# CBASS_RC0_QOS register map
Vendor: Texas Instruments
Peripheral module from a debugger description file (folder J7_AHP).
Registers are 32-bit, read-write, reset 0x0 unless marked. A register's access mark holds for its fields unless they carry their own. Offsets are as the file gives them; lines under a group give offsets from that group; [hi:lo] are bit positions; {n}, {i} and the like mark numbered series; 'fields as' and 'values as' point back to an identical list; <NAME> marks a mode.

## CBASS_RC0_QOS
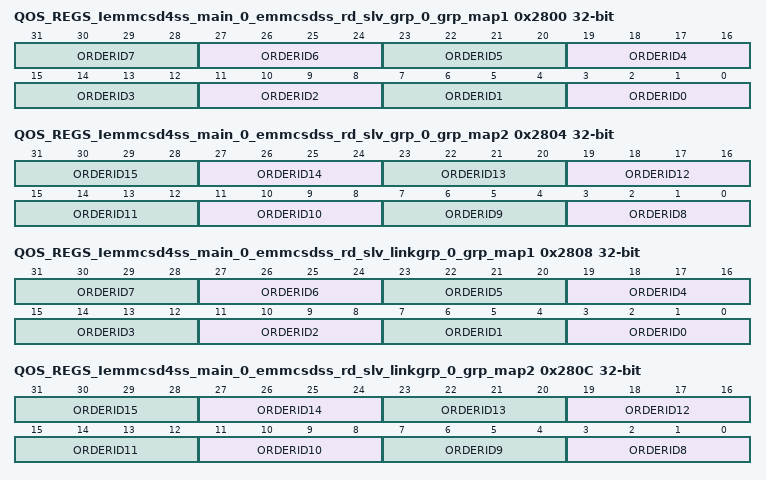
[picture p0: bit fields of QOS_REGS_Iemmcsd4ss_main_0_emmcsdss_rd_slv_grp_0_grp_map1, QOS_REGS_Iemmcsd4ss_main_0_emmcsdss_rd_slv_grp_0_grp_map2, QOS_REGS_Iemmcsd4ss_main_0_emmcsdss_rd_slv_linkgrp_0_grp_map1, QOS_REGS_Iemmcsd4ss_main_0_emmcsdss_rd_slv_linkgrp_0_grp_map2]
0x2800 QOS_REGS_Iemmcsd4ss_main_0_emmcsdss_rd_slv_grp_0_grp_map1
  [4n+3:4n] ORDERID{n} (n=0..7) — orderid signal for {n}.
0x2804 QOS_REGS_Iemmcsd4ss_main_0_emmcsdss_rd_slv_grp_0_grp_map2
  [4n-29:4n-32] ORDERID{n} (n=8..15) — orderid signal for {n-8}.
0x2808 QOS_REGS_Iemmcsd4ss_main_0_emmcsdss_rd_slv_linkgrp_0_grp_map1
  [4n+3:4n] ORDERID{n} (n=0..7) — orderid signal for {n}.
0x280C QOS_REGS_Iemmcsd4ss_main_0_emmcsdss_rd_slv_linkgrp_0_grp_map2
  [4n-29:4n-32] ORDERID{n} (n=8..15) — orderid signal for {n-8}.
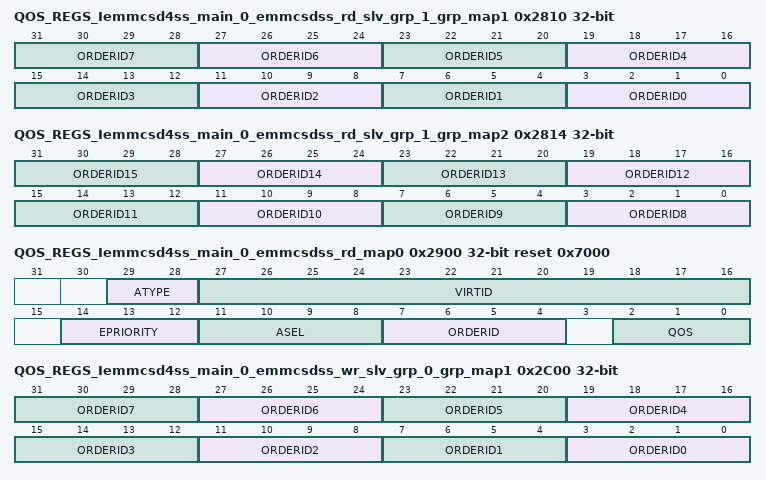
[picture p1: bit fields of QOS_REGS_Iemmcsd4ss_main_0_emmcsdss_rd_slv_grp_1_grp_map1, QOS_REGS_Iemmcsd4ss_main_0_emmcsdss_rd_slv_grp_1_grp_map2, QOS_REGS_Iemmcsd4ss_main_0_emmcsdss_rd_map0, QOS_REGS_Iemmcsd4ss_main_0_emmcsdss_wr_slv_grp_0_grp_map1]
0x2810 QOS_REGS_Iemmcsd4ss_main_0_emmcsdss_rd_slv_grp_1_grp_map1
  [4n+3:4n] ORDERID{n} (n=0..7) — orderid signal for {n}.
0x2814 QOS_REGS_Iemmcsd4ss_main_0_emmcsdss_rd_slv_grp_1_grp_map2
  [4n-29:4n-32] ORDERID{n} (n=8..15) — orderid signal for {n-8}.
0x2900 QOS_REGS_Iemmcsd4ss_main_0_emmcsdss_rd_map0 reset 0x7000
  [29:28] ATYPE — epriority signal for channel N. 0 = physical. 1 = intermediate. 2 = virtual. 3 = physical with coherence.
  [27:16] VIRTID — virtid signal for channel N.
  [14:12] EPRIORITY — epriority signal for channel N.
  [11:8] ASEL — asel signal for channel N. 0 = SOC address. 1-15 = peripheral address.
  [7:4] ORDERID — orderid signal for channel N.
  [2:0] QOS — qos signal for channel N.
0x2C00 QOS_REGS_Iemmcsd4ss_main_0_emmcsdss_wr_slv_grp_0_grp_map1
  [4n+3:4n] ORDERID{n} (n=0..7) — orderid signal for {n}.
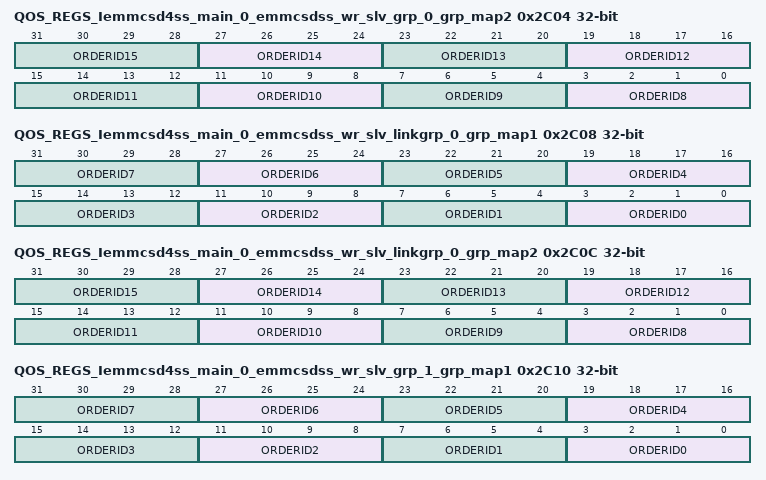
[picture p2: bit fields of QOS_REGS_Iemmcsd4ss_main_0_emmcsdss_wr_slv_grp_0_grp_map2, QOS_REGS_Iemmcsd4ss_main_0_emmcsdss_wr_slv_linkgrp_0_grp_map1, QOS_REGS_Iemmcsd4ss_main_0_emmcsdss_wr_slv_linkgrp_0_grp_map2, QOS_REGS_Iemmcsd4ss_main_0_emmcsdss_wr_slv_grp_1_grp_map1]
0x2C04 QOS_REGS_Iemmcsd4ss_main_0_emmcsdss_wr_slv_grp_0_grp_map2
  [4n-29:4n-32] ORDERID{n} (n=8..15) — orderid signal for {n-8}.
0x2C08 QOS_REGS_Iemmcsd4ss_main_0_emmcsdss_wr_slv_linkgrp_0_grp_map1
  [4n+3:4n] ORDERID{n} (n=0..7) — orderid signal for {n}.
0x2C0C QOS_REGS_Iemmcsd4ss_main_0_emmcsdss_wr_slv_linkgrp_0_grp_map2
  [4n-29:4n-32] ORDERID{n} (n=8..15) — orderid signal for {n-8}.
0x2C10 QOS_REGS_Iemmcsd4ss_main_0_emmcsdss_wr_slv_grp_1_grp_map1
  [4n+3:4n] ORDERID{n} (n=0..7) — orderid signal for {n}.
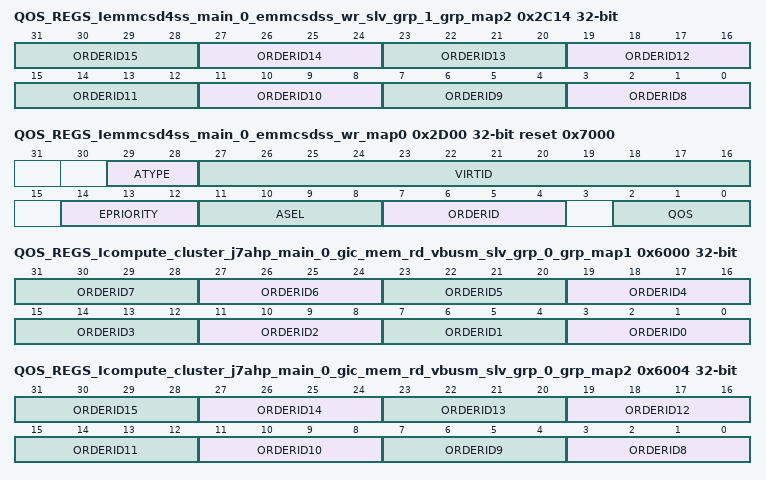
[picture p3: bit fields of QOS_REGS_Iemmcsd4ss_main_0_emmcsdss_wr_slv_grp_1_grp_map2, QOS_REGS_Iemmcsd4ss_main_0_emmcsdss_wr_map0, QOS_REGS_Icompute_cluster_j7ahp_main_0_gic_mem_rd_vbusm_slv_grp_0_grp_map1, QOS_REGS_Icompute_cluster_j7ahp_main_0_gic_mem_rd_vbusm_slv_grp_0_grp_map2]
0x2C14 QOS_REGS_Iemmcsd4ss_main_0_emmcsdss_wr_slv_grp_1_grp_map2
  [4n-29:4n-32] ORDERID{n} (n=8..15) — orderid signal for {n-8}.
0x2D00 QOS_REGS_Iemmcsd4ss_main_0_emmcsdss_wr_map0 reset 0x7000
  fields as QOS_REGS_Iemmcsd4ss_main_0_emmcsdss_rd_map0
0x6000 QOS_REGS_Icompute_cluster_j7ahp_main_0_gic_mem_rd_vbusm_slv_grp_0_grp_map1
  [4n+3:4n] ORDERID{n} (n=0..7) — orderid signal for {n}.
0x6004 QOS_REGS_Icompute_cluster_j7ahp_main_0_gic_mem_rd_vbusm_slv_grp_0_grp_map2
  [4n-29:4n-32] ORDERID{n} (n=8..15) — orderid signal for {n-8}.
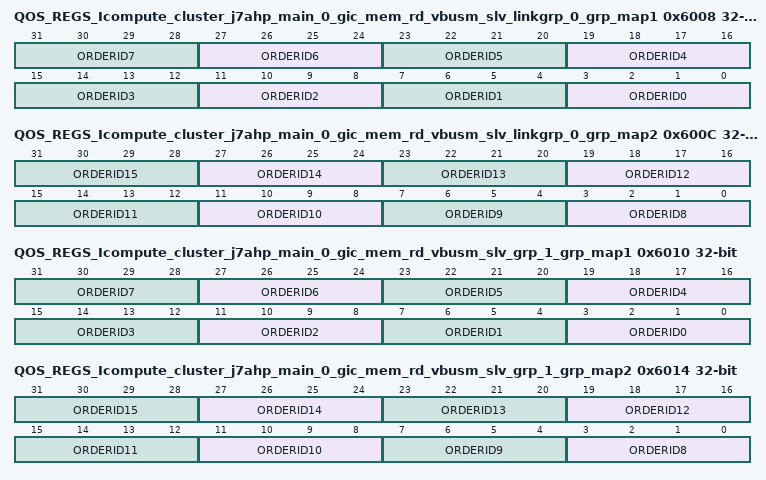
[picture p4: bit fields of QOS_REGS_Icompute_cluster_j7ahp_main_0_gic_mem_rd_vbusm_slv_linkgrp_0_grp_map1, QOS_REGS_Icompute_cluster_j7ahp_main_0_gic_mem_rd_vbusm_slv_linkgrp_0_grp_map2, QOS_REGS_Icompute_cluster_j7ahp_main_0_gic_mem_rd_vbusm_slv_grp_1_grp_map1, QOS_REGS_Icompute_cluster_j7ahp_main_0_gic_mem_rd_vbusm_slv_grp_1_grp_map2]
0x6008 QOS_REGS_Icompute_cluster_j7ahp_main_0_gic_mem_rd_vbusm_slv_linkgrp_0_grp_map1
  [4n+3:4n] ORDERID{n} (n=0..7) — orderid signal for {n}.
0x600C QOS_REGS_Icompute_cluster_j7ahp_main_0_gic_mem_rd_vbusm_slv_linkgrp_0_grp_map2
  [4n-29:4n-32] ORDERID{n} (n=8..15) — orderid signal for {n-8}.
0x6010 QOS_REGS_Icompute_cluster_j7ahp_main_0_gic_mem_rd_vbusm_slv_grp_1_grp_map1
  [4n+3:4n] ORDERID{n} (n=0..7) — orderid signal for {n}.
0x6014 QOS_REGS_Icompute_cluster_j7ahp_main_0_gic_mem_rd_vbusm_slv_grp_1_grp_map2
  [4n-29:4n-32] ORDERID{n} (n=8..15) — orderid signal for {n-8}.
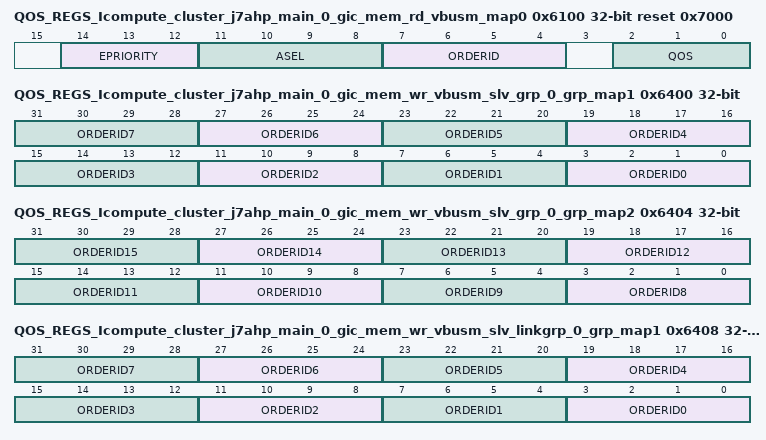
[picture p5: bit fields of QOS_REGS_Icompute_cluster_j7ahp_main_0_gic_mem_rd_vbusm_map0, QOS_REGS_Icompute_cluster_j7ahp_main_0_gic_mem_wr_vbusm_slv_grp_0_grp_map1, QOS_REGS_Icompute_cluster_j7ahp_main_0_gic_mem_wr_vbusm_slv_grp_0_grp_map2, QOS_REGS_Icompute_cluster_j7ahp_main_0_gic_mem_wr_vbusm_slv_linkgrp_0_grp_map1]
0x6100 QOS_REGS_Icompute_cluster_j7ahp_main_0_gic_mem_rd_vbusm_map0 reset 0x7000
  [14:12] EPRIORITY — epriority signal for channel N.
  [11:8] ASEL — asel signal for channel N. 0 = SOC address. 1-15 = peripheral address.
  [7:4] ORDERID — orderid signal for channel N.
  [2:0] QOS — qos signal for channel N.
0x6400 QOS_REGS_Icompute_cluster_j7ahp_main_0_gic_mem_wr_vbusm_slv_grp_0_grp_map1
  [4n+3:4n] ORDERID{n} (n=0..7) — orderid signal for {n}.
0x6404 QOS_REGS_Icompute_cluster_j7ahp_main_0_gic_mem_wr_vbusm_slv_grp_0_grp_map2
  [4n-29:4n-32] ORDERID{n} (n=8..15) — orderid signal for {n-8}.
0x6408 QOS_REGS_Icompute_cluster_j7ahp_main_0_gic_mem_wr_vbusm_slv_linkgrp_0_grp_map1
  [4n+3:4n] ORDERID{n} (n=0..7) — orderid signal for {n}.
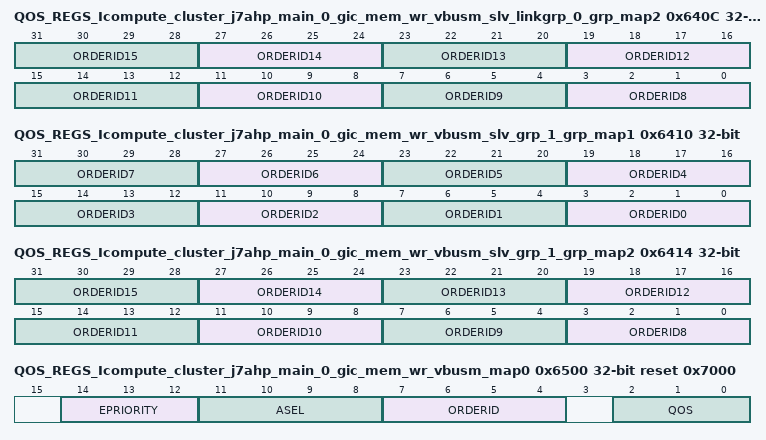
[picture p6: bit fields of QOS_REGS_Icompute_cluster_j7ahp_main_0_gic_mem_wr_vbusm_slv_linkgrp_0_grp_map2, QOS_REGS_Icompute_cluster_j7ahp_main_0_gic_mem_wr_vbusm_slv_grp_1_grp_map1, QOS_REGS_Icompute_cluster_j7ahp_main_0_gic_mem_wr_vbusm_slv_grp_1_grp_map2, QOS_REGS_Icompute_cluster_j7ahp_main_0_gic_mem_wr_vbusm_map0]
0x640C QOS_REGS_Icompute_cluster_j7ahp_main_0_gic_mem_wr_vbusm_slv_linkgrp_0_grp_map2
  [4n-29:4n-32] ORDERID{n} (n=8..15) — orderid signal for {n-8}.
0x6410 QOS_REGS_Icompute_cluster_j7ahp_main_0_gic_mem_wr_vbusm_slv_grp_1_grp_map1
  [4n+3:4n] ORDERID{n} (n=0..7) — orderid signal for {n}.
0x6414 QOS_REGS_Icompute_cluster_j7ahp_main_0_gic_mem_wr_vbusm_slv_grp_1_grp_map2
  [4n-29:4n-32] ORDERID{n} (n=8..15) — orderid signal for {n-8}.
0x6500 QOS_REGS_Icompute_cluster_j7ahp_main_0_gic_mem_wr_vbusm_map0 reset 0x7000
  fields as QOS_REGS_Icompute_cluster_j7ahp_main_0_gic_mem_rd_vbusm_map0
